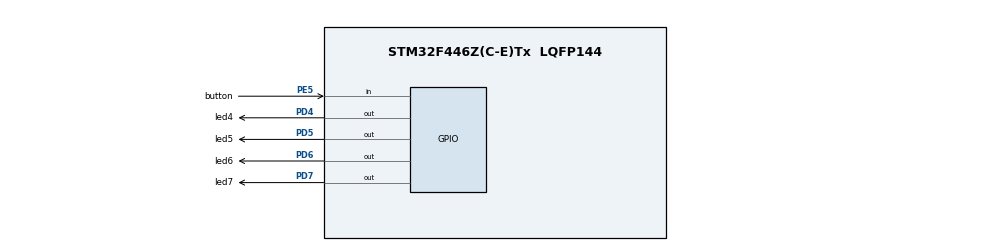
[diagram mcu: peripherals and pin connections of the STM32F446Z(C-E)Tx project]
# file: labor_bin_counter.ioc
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Mcu.Family=STM32F4
Mcu.Name=STM32F446Z(C-E)Tx
Mcu.Package=LQFP144
NVIC.PriorityGroup=NVIC_PRIORITYGROUP_4
PD4.GPIO_Label=led4
PD4.Signal=GPIO_Output
PD5.GPIO_Label=led5
PD5.Signal=GPIO_Output
PD6.GPIO_Label=led6
PD6.Signal=GPIO_Output
PD7.GPIO_Label=led7
PD7.Signal=GPIO_Output
PE5.GPIO_Label=button
PE5.GPIO_PuPd=GPIO_PULLDOWN
PE5.Signal=GPIO_Input
ProjectManager.HeapSize=0x200
ProjectManager.StackSize=0x400
ProjectManager.TargetToolchain=STM32CubeIDE
RCC.CortexFreq_Value=16000000
RCC.USBFreq_Value=96000000
RCC.VCOOutputFreq_Value=192000000
board=custom

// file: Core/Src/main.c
/* USER CODE BEGIN Header */
/**
  ******************************************************************************
  * @file           : main.c
  * @brief          : Main program body
  ******************************************************************************
  * @attention
  *
  * Copyright (c) 2026 STMicroelectronics.
  * All rights reserved.
  *
  * This software is licensed under terms that can be found in the LICENSE file
  * in the root directory of this software component.
  * If no LICENSE file comes with this software, it is provided AS-IS.
  *
  ******************************************************************************
  */
/* USER CODE END Header */
#include "main.h"

void SystemClock_Config(void);
static void MX_GPIO_Init(void);

int main(void)
{

  /* MCU Configuration--------------------------------------------------------*/

  /* Reset of all peripherals, Initializes the Flash interface and the Systick. */
  HAL_Init();

  /* Configure the system clock */
  SystemClock_Config();

  /* Initialize all configured peripherals */
  MX_GPIO_Init();

  /* Infinite loop */
  /* USER CODE BEGIN WHILE */
  int state = 0x01;
  // ----------
  // main loop
  //-----------
  while (1)
  {
	  //state változó értékvizsgálat
	  // check which led to light up
	  HAL_GPIO_WritePin(led4_GPIO_Port, led4_Pin, state & 0x01? GPIO_PIN_SET : GPIO_PIN_RESET);
	  HAL_GPIO_WritePin(led5_GPIO_Port, led5_Pin, state & 0x02? GPIO_PIN_SET : GPIO_PIN_RESET);
	  HAL_GPIO_WritePin(led6_GPIO_Port, led6_Pin, state & 0x04? GPIO_PIN_SET : GPIO_PIN_RESET);
	  HAL_GPIO_WritePin(led7_GPIO_Port, led7_Pin, state & 0x08 ? GPIO_PIN_SET : GPIO_PIN_RESET);

	  // shift the leds (shift the state variable)
	  state <<= 1;

	  // if the state reached 16 then reset it.
	  if (state == 0x10)
	  {
		  state = 0x01;
	  }

	  // delay
	  HAL_Delay(100);
    /* USER CODE END WHILE */
  }
}

void SystemClock_Config(void)
{
  RCC_OscInitTypeDef RCC_OscInitStruct = {0};
  RCC_ClkInitTypeDef RCC_ClkInitStruct = {0};

  /** Configure the main internal regulator output voltage
  */
  __HAL_RCC_PWR_CLK_ENABLE();
  __HAL_PWR_VOLTAGESCALING_CONFIG(PWR_REGULATOR_VOLTAGE_SCALE3);

  /** Initializes the RCC Oscillators according to the specified parameters
  * in the RCC_OscInitTypeDef structure.
  */
  RCC_OscInitStruct.OscillatorType = RCC_OSCILLATORTYPE_HSI;
  RCC_OscInitStruct.HSIState = RCC_HSI_ON;
  RCC_OscInitStruct.HSICalibrationValue = RCC_HSICALIBRATION_DEFAULT;
  RCC_OscInitStruct.PLL.PLLState = RCC_PLL_NONE;
  if (HAL_RCC_OscConfig(&RCC_OscInitStruct) != HAL_OK)
  {
    Error_Handler();
  }

  /** Initializes the CPU, AHB and APB buses clocks
  */
  RCC_ClkInitStruct.ClockType = RCC_CLOCKTYPE_HCLK|RCC_CLOCKTYPE_SYSCLK
                              |RCC_CLOCKTYPE_PCLK1|RCC_CLOCKTYPE_PCLK2;
  RCC_ClkInitStruct.SYSCLKSource = RCC_SYSCLKSOURCE_HSI;
  RCC_ClkInitStruct.AHBCLKDivider = RCC_SYSCLK_DIV1;
  RCC_ClkInitStruct.APB1CLKDivider = RCC_HCLK_DIV1;
  RCC_ClkInitStruct.APB2CLKDivider = RCC_HCLK_DIV1;

  if (HAL_RCC_ClockConfig(&RCC_ClkInitStruct, FLASH_LATENCY_0) != HAL_OK)
  {
    Error_Handler();
  }
}

static void MX_GPIO_Init(void)
{
  GPIO_InitTypeDef GPIO_InitStruct = {0};

  /* GPIO Ports Clock Enable */
  __HAL_RCC_GPIOE_CLK_ENABLE();
  __HAL_RCC_GPIOD_CLK_ENABLE();

  /*Configure GPIO pin Output Level */
  HAL_GPIO_WritePin(GPIOD, led4_Pin|led5_Pin|led6_Pin|led7_Pin, GPIO_PIN_RESET);

  /*Configure GPIO pin : button_Pin */
  GPIO_InitStruct.Pin = button_Pin;
  GPIO_InitStruct.Mode = GPIO_MODE_INPUT;
  GPIO_InitStruct.Pull = GPIO_PULLDOWN;
  HAL_GPIO_Init(button_GPIO_Port, &GPIO_InitStruct);

  /*Configure GPIO pins : led4_Pin led5_Pin led6_Pin led7_Pin */
  GPIO_InitStruct.Pin = led4_Pin|led5_Pin|led6_Pin|led7_Pin;
  GPIO_InitStruct.Mode = GPIO_MODE_OUTPUT_PP;
  GPIO_InitStruct.Pull = GPIO_NOPULL;
  GPIO_InitStruct.Speed = GPIO_SPEED_FREQ_LOW;
  HAL_GPIO_Init(GPIOD, &GPIO_InitStruct);

}

void Error_Handler(void)
{
  __disable_irq();
  while (1)
  {
  }
}
